VERSION ""

NS_ :

BS_:

BU_:
VAL_TABLE_ Brake_Lights 1 "True" 0 "False" ;
VAL_TABLE_ Main_Light_Switch 0 "Auto" 1 "Off" 2 "Parking light" 3 "Headlights" ;
VAL_TABLE_ Low_Beam 0 "False" 1 "True" ;
VAL_TABLE_ High_Beam 0 "False" 1 "True" ;
VAL_TABLE_ Electric_Park_Brake_Switch 0 "Not On " 1 "Release" 2 "apply" 3 "Active" ;
VAL_TABLE_ Brake_to_release_Parking_Brake 1 "True" ;
VAL_TABLE_ Parking_Brake_State 1 "Parking Brake Active" 0 "Parking Brake Inactive" ;
VAL_TABLE_ HndsOffStrWhlDtSt 0 "Hands Off" 1 "Hands On" ;
VAL_TABLE_ HndsOffStrWhlDtMd 0 "Disabled" 1 "Enabled" 2 "Failed" ;
VAL_TABLE_ ABSPr 1 "true" 0 "false" ;
VAL_TABLE_ ABSIO 1 "true" 0 "false" ;
VAL_TABLE_ AutoBrkngAvlbl 1 "true" 0 "false" ;
VAL_TABLE_ ABSActvProt 1 "true" 0 "false" ;
VAL_TABLE_ AutoBrkngAct 1 "true" 0 "false" ;
VAL_TABLE_ TCSysDisSwAtv_12A 1 "true" 0 "false" ;
VAL_TABLE_ Ky_IdDevPr 1 "true" 0 "false" ;
VAL_TABLE_ PsSbltAtc 1 "true" 0 "false" ;
VAL_TABLE_ LnCat 3 "Four Or More Lanes" 2 "Two Or Three Lanes" 1 "One lane" 0 "no info available" ;
VAL_TABLE_ RRDoorAjarSwAct 1 "true" 0 "false" ;
VAL_TABLE_ PDAjrSwAtv 1 "true" 0 "false" ;
VAL_TABLE_ DDAjrSwAtv 1 "true" 0 "false" ;
VAL_TABLE_ RLDoorAjarSwAct 1 "true" 0 "false" ;
VAL_TABLE_ DrSbltAtc 1 "true" 0 "false" ;
VAL_TABLE_ FwdClnAlrtPr 1 "true" 0 "false" ;
VAL_TABLE_ ACCAct370 1 "true" 0 "false" ;
VAL_TABLE_ DrvThrtlOvrdIO 1 "true" 0 "false" ;

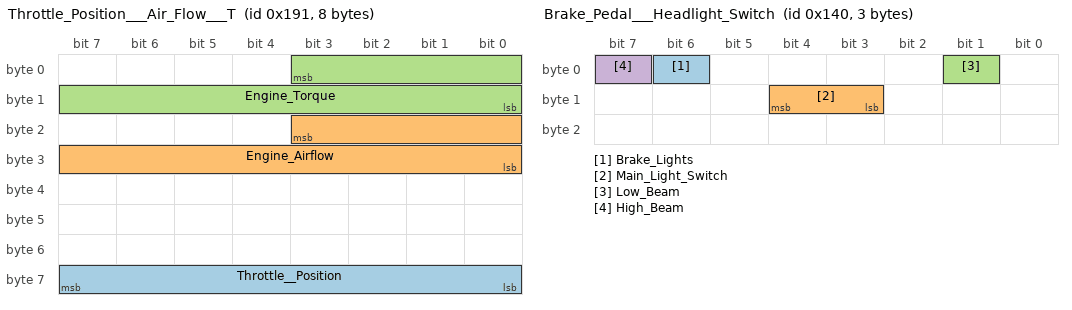
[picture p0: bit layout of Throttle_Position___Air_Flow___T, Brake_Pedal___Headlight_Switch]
BO_ 401 Throttle_Position___Air_Flow___T: 8 Vector__XXX
 SG_ Throttle__Position : 63|8@0+ (0.392157,0) [0|100.000035] "%" Vector__XXX
 SG_ Engine_Airflow : 19|12@0+ (0.5,-848) [-848|1199.5] "Nm" Vector__XXX
 SG_ Engine_Torque : 3|12@0+ (0.5,-848) [-848|1199.5] "Nm" Vector__XXX

BO_ 320 Brake_Pedal___Headlight_Switch: 3 Vector__XXX
 SG_ Brake_Lights : 6|1@0+ (1,0) [0|1] "" Vector__XXX
 SG_ Main_Light_Switch : 12|2@0+ (1,0) [0|3] "N/A" Vector__XXX
 SG_ Low_Beam : 1|1@0+ (1,0) [0|1] "" Vector__XXX
 SG_ High_Beam : 7|1@0+ (1,0) [0|1] "" Vector__XXX

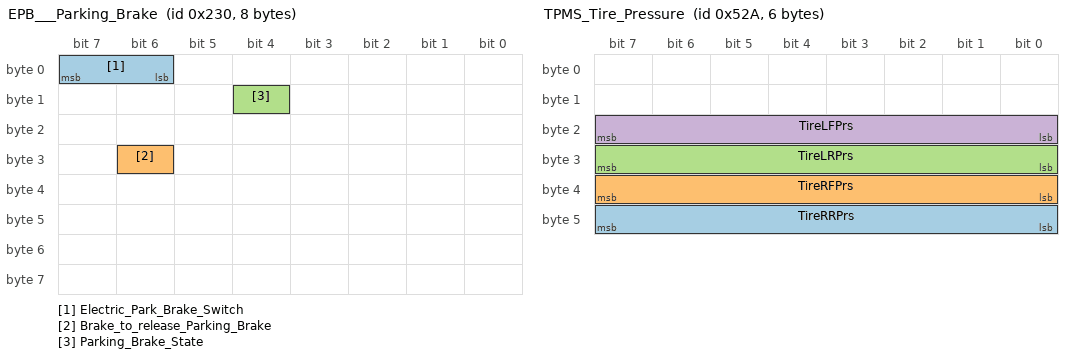
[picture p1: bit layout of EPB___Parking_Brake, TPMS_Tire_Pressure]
BO_ 560 EPB___Parking_Brake: 8 Vector__XXX
 SG_ Electric_Park_Brake_Switch : 7|2@0+ (1,0) [0|3] "" Vector__XXX
 SG_ Brake_to_release_Parking_Brake : 30|1@0+ (1,0) [0|1] "" Vector__XXX
 SG_ Parking_Brake_State : 12|1@0+ (1,0) [0|1] "" Vector__XXX

BO_ 288 ODO_Odometer: 5 Vector__XXX
 SG_ Vehicle_Odometer : 7|32@0+ (0.015625,0) [0|67108863.984375] "km" Vector__XXX

BO_ 1322 TPMS_Tire_Pressure: 6 Vector__XXX
 SG_ TireRRPrs : 47|8@0+ (4,0) [0|1020] "kPaG" CGM_HS,LVMPC_HS,EDI_HS,ICCM_OBD_HS,ICCM_HS,RDCM_HS,EBCM_OBD_HS,EBCM_HS
 SG_ TireRFPrs : 39|8@0+ (4,0) [0|1020] "kPaG" CGM_HS,LVMPC_HS,EDI_HS,ICCM_OBD_HS,ICCM_HS,RDCM_HS,EBCM_OBD_HS,EBCM_HS
 SG_ TireLRPrs : 31|8@0+ (4,0) [0|1020] "kPaG" CGM_HS,LVMPC_HS,EDI_HS,ICCM_OBD_HS,ICCM_HS,RDCM_HS,EBCM_OBD_HS,EBCM_HS
 SG_ TireLFPrs : 23|8@0+ (4,0) [0|1020] "kPaG" CGM_HS,LVMPC_HS,EDI_HS,ICCM_OBD_HS,ICCM_HS,RDCM_HS,EBCM_OBD_HS,EBCM_HS

BO_ 1020 OAT_Outside_Air_Temperature: 8 Vector__XXX
 SG_ OtsAirTmp : 31|8@0+ (0.5,-40) [-40|87.5] "deg C" CGM_HS,EPB_HS,BSM_HS,VICM_HS,PFAF_HS,BCM_HS

BO_ 388 LKA_Lane_Keeping_Assist___Active: 8 Vector__XXX
 SG_ HndsOffStrWhlDtSt : 21|1@0+ (1,0) [0|1] "" CGM_HS,EOCM_F_HS,FCM_HS
 SG_ HndsOffStrWhlDtMd : 20|2@0+ (1,0) [0|2] "" CGM_HS,EOCM_F_HS,FCM_HS

BO_ 381 ABS: 8 Vector__XXX
 SG_ ABSPr : 22|1@0+ (1,0) [0|1] "" CGM_HS,BCP_HS,APPS_HS,BCM_HS,EPB_HS
 SG_ ABSIO : 12|1@0+ (1,0) [0|1] "" CGM_HS,FCM_HS,EOCM_F_HS,BCM_HS

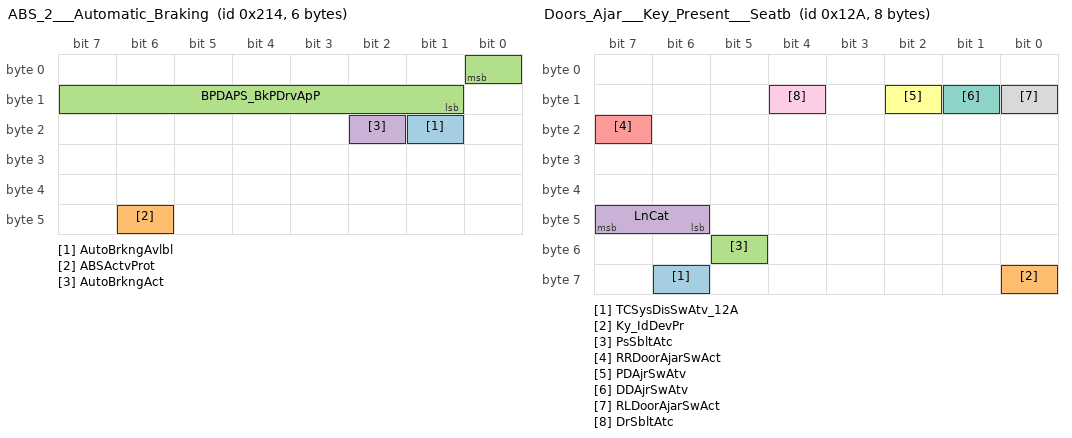
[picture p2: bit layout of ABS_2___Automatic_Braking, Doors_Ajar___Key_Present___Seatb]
BO_ 532 ABS_2___Automatic_Braking: 6 Vector__XXX
 SG_ AutoBrkngAvlbl : 17|1@0+ (1,0) [0|1] "" FCM_HS,CGM_HS,EPS_HS,EOCM_F_HS,EPB_HS
 SG_ ABSActvProt : 46|1@0+ (1,0) [0|1] "" CGM_HS,EPS_HS,EOCM_F_HS,ICCM_OBD_HS,ICCM_HS
 SG_ BPDAPS_BkPDrvApP : 0|8@0+ (75,0) [0|19125] "kPa" CGM_HS,FCM_HS,EOCM_F_HS,ICCM_OBD_HS,ICCM_HS,BCM_HS,ACC_HS,SADS_HS,EPB_HS
 SG_ AutoBrkngAct : 18|1@0+ (1,0) [0|1] "" CGM_HS,ICCM_OBD_HS,ICCM_HS,EPB_HS,ACC_HS

BO_ 298 Doors_Ajar___Key_Present___Seatb: 8 Vector__XXX
 SG_ TCSysDisSwAtv_12A : 62|1@0+ (1,0) [0|1] "" CGM_HS,ECM_HS
 SG_ Ky_IdDevPr : 56|1@0+ (1,0) [0|1] "" CGM_HS,EBCM_OBD_HS,EBCM_HS,EPB_HS
 SG_ PsSbltAtc : 53|1@0+ (1,0) [0|1] "" CGM_HS,EBCM_OBD_HS,EBCM_HS
 SG_ LnCat : 47|2@0+ (1,0) [0|3] "" CGM_HS,FCM_HS,AHL_AFL_HS
 SG_ RRDoorAjarSwAct : 23|1@0+ (1,0) [0|1] "" CGM_HS,ICCM_OBD_HS,ICCM_HS,ALC_HS,EPB_HS,SADS_HS
 SG_ PDAjrSwAtv : 10|1@0+ (1,0) [0|1] "" CGM_HS,EPB_HS,ICCM_OBD_HS,ICCM_HS,ALC_HS,SADS_HS
 SG_ DDAjrSwAtv : 9|1@0+ (1,0) [0|1] "" CGM_HS,ECM_HS,EBCM_OBD_HS,EBCM_HS,ACC_HS,EPB_HS,ICCM_OBD_HS,ICCM_HS,ALC_HS,SADS_HS
 SG_ RLDoorAjarSwAct : 8|1@0+ (1,0) [0|1] "" CGM_HS,ICCM_OBD_HS,ICCM_HS,ALC_HS,EPB_HS,SADS_HS
 SG_ DrSbltAtc : 12|1@0+ (1,0) [0|1] "" CGM_HS,ECM_HS,ACC_HS,EPB_HS,EBCM_OBD_HS,EBCM_HS

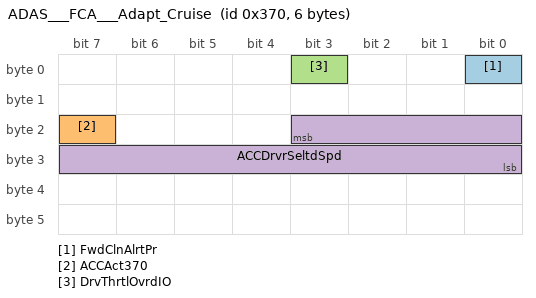
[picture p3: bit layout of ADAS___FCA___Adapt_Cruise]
BO_ 880 ADAS___FCA___Adapt_Cruise: 6 Vector__XXX
 SG_ FwdClnAlrtPr : 0|1@0+ (1,0) [0|1] "" BCM_HS
 SG_ ACCAct370 : 23|1@0+ (1,0) [0|1] "" EBCM_OBD_HS,EBCM_HS,TCM_HS,BCM_HS
 SG_ DrvThrtlOvrdIO : 3|1@0+ (1,0) [0|1] "" BCM_HS
 SG_ ACCDrvrSeltdSpd : 19|12@0+ (0.0625,0) [0|255.9375] "km / h" ECM_HS,BCM_HS

BO_ 1217 Engine_Cooling_Temperature: 8 Vector__XXX
 SG_ Engine_Cooling_Temperature_ECT : 23|8@0+ (1,-40) [-40|215] "deg C" Vector__XXX

BO_ 810 GPS_Lat_Lon: 8 Vector__XXX
 SG_ PsngSysLong : 38|31@0- (1,0) [-1073741824|1073741823] "ms arc" CGM_HS,LVMPC_HS,EBCM_OBD_HS,EBCM_HS,ACC_HS
 SG_ PsngSysLat : 5|30@0- (1,0) [-536870912|536870911] "ms arc" CGM_HS,LVMPC_HS,EBCM_OBD_HS,EBCM_HS,ACC_HS

BO_ 390 canFdStandard: 24 Vector__XXX
 SG_ signal3 : 128|8@1- (1,0) [0|255] "" Vector__XXX
 SG_ signal2 : 64|8@1- (1,0) [0|255] "" Vector__XXX
 SG_ signal1 : 0|8@1- (1,0) [0|255] "" Vector__XXX

BO_ 2633937150 TTI2: 20 Vector__XXX
 SG_ TripAirCompressorOnTime : 128|32@1+ (0.05,0) [0|210554060.75] "hr" Vector__XXX
 SG_ TripIdleTime : 96|32@1+ (0.05,0) [0|210554060.75] "hr" Vector__XXX
 SG_ TripEngRunningTime : 64|32@1+ (0.05,0) [0|210554060.75] "hr" Vector__XXX
 SG_ TripCruiseTime : 0|32@1+ (0.05,0) [0|210554060.75] "hr" Vector__XXX
 SG_ TripPTOGovernorTime : 32|32@1+ (0.05,0) [0|210554060.75] "hr" Vector__XXX

BO_ 2633938174 TTI1: 64 Vector__XXX
 SG_ TripTimeInDerateByEngHigherBits4 : 496|16@1+ (1,0) [0|4294967295] "hr" Vector__XXX
 SG_ TripTimeInDerateByEngHigherBits3 : 480|16@1+ (1,0) [0|4294967295] "hr" Vector__XXX
 SG_ TripTimeInDerateByEngHigherBits2 : 448|32@1+ (1,0) [0|4294967295] "hr" Vector__XXX
 SG_ TripTimeInDerateByEngHigherBits1 : 416|32@1+ (1,0) [0|4294967295] "hr" Vector__XXX
 SG_ TripTimeInDerateByEngMediumBits5 : 300|32@1+ (1,0) [0|4294967295] "hr" Vector__XXX
 SG_ TripTimeInDerateByEngMediumBits4 : 256|44@1+ (1,0) [0|4294967295] "hr" Vector__XXX
 SG_ TripTimeInDerateByEngMediumBits3 : 224|32@1+ (1,0) [0|4294967295] "hr" Vector__XXX
 SG_ TripTimeInDerateByEngMediumBits2 : 192|32@1+ (1,0) [0|4294967295] "hr" Vector__XXX
 SG_ TripTimeInDerateByEngMediumBits1 : 128|64@1+ (1,0) [0|4294967295] "hr" Vector__XXX
 SG_ TripTimeInDerateByEng : 96|32@1+ (0.05,0) [0|210554060.75] "hr" Vector__XXX
 SG_ TripTimeInGearDown : 64|32@1+ (0.05,0) [0|210554060.75] "hr" Vector__XXX
 SG_ TripTimeInTopGear : 32|32@1+ (0.05,0) [0|210554060.75] "hr" Vector__XXX
 SG_ TripTimeInVSL : 0|32@1+ (0.05,0) [0|210554060.75] "hr" Vector__XXX

BO_ 2566748670 AT1TI: 32 Vector__XXX
 SG_ Aftrtrtmnt1TrpNmbrOfActvRgnrtnMn : 224|32@1+ (1,0) [0|4294967295] "counts" Vector__XXX
 SG_ Aftrtrtmnt1TrpNmbrOfActvRgnrtnIn : 192|32@1+ (1,0) [0|4294967295] "counts" Vector__XXX
 SG_ Aftrtrtmnt1TrpNmbrOfPssvRgnrtns : 160|32@1+ (1,0) [0|4294967295] "counts" Vector__XXX
 SG_ Aftrtrtmnt1TrpPssvRgnrationTime : 128|32@1+ (1,0) [0|4211081215] "s" Vector__XXX
 SG_ Aftrtrtmnt1TrpNmbrOfActvRgnrtns : 96|32@1+ (1,0) [0|4294967295] "counts" Vector__XXX
 SG_ Aftertreatment1TripDisabledTime : 64|32@1+ (1,0) [0|4211081215] "s" Vector__XXX
 SG_ Aftrtrtmnt1TrpActvRgnrationTime : 32|32@1+ (1,0) [0|4211081215] "s" Vector__XXX
 SG_ Aftertreatment1TripFuelUsed : 0|32@1+ (0.5,0) [0|2105540607.5] "L" Vector__XXX

BO_ 350 AT2HI: 36 Vector__XXX
 SG_ Aftrtrtmnt2AvrgTmBtwnActvRgnrtns : 256|32@1+ (1,0) [0|4211081215] "s" Vector__XXX
 SG_ Aftrtrtmnt2TtlNmbrOfActvRgnrtnMn : 224|32@1+ (1,0) [0|4294967295] "counts" Vector__XXX
 SG_ Aftrtrtmnt2TtlNmbrOfActvRgnrtnIn : 192|32@1+ (1,0) [0|4294967295] "counts" Vector__XXX
 SG_ Aftrtrtmnt2TtlNmbrOfPssvRgnrtns : 160|32@1+ (1,0) [0|4294967295] "counts" Vector__XXX
 SG_ Aftrtrtmnt2TtlPssvRgnrationTime : 128|32@1+ (1,0) [0|4211081215] "s" Vector__XXX
 SG_ Aftrtrtmnt2TtlNmbrOfActvRgnrtns : 96|32@1+ (1,0) [0|4294967295] "counts" Vector__XXX
 SG_ Aftrtreatment2TotalDisabledTime : 64|32@1+ (1,0) [0|4211081215] "s" Vector__XXX
 SG_ Aftrtrtmnt2TtalRegenerationTime : 32|32@1+ (1,0) [0|4211081215] "s" Vector__XXX
 SG_ Aftertreatment2TotalFuelUsed : 0|32@1+ (0.5,0) [0|2105540607.5] "L" Vector__XXX

BA_DEF_ "BusType" STRING;

BA_DEF_ SG_  "SignalType" STRING ;
BA_DEF_ SG_  "SignalLongName" STRING ;
BA_DEF_ BO_  "GenMsgCycleTime" INT 0 10000;
BA_DEF_DEF_  "SignalType" "";
BA_DEF_DEF_  "SignalLongName" "";
BA_DEF_DEF_  "GenMsgCycleTime" 0;
BA_ "BusType" "CAN FD";
BA_ "GenMsgCycleTime" BO_ 401 12;
BA_ "GenMsgCycleTime" BO_ 320 1000;
BA_ "GenMsgCycleTime" BO_ 560 50;
BA_ "GenMsgCycleTime" BO_ 288 5000;
BA_ "GenMsgCycleTime" BO_ 1322 1000;
BA_ "GenMsgCycleTime" BO_ 1020 250;
BA_ "GenMsgCycleTime" BO_ 388 100;
BA_ "GenMsgCycleTime" BO_ 381 100;
BA_ "GenMsgCycleTime" BO_ 532 50;
BA_ "GenMsgCycleTime" BO_ 298 100;
BA_ "GenMsgCycleTime" BO_ 810 100;
BA_ "GenMsgCycleTime" BO_ 880 40;
BA_ "GenMsgCycleTime" BO_ 1217 500;
BA_ "GenMsgCycleTime" BO_ 390 142;
BA_ "GenMsgCycleTime" BO_ 2633937150 30;
BA_ "GenMsgCycleTime" BO_ 2633938174 30;
BA_ "GenMsgCycleTime" BO_ 350 30;
BA_ "GenMsgCycleTime" BO_ 2566748670 30;
BA_ "SignalType" SG_ 2633938174 TripTimeInDerateByEng "ENM";
BA_ "SignalType" SG_ 2633938174 TripTimeInDerateByEngHigherBits1 "ENM";
BA_ "SignalType" SG_ 2633938174 TripTimeInDerateByEngHigherBits2 "ENM";
BA_ "SignalType" SG_ 2633938174 TripTimeInDerateByEngHigherBits3 "ENM";
BA_ "SignalType" SG_ 2633938174 TripTimeInDerateByEngHigherBits4 "ENM";
BA_ "SignalType" SG_ 2633938174 TripTimeInDerateByEngMediumBits1 "ENM";
BA_ "SignalType" SG_ 2633938174 TripTimeInDerateByEngMediumBits2 "ENM";
BA_ "SignalType" SG_ 2633938174 TripTimeInDerateByEngMediumBits3 "ENM";
BA_ "SignalType" SG_ 2633938174 TripTimeInDerateByEngMediumBits4 "ENM";
BA_ "SignalType" SG_ 2633938174 TripTimeInDerateByEngMediumBits5 "ENM";
BA_ "SignalType" SG_ 2633938174 TripTimeInGearDown "ENM";
BA_ "SignalType" SG_ 2633938174 TripTimeInTopGear "ENM";
BA_ "SignalType" SG_ 2633938174 TripTimeInVSL "ENM";
BA_ "SignalType" SG_ 320 Brake_Lights "ENM";
BA_ "SignalType" SG_ 320 Main_Light_Switch "ENM";
BA_ "SignalType" SG_ 320 Low_Beam "ENM";
BA_ "SignalType" SG_ 320 High_Beam "ENM";
BA_ "SignalType" SG_ 560 Electric_Park_Brake_Switch "ENM";
BA_ "SignalType" SG_ 560 Brake_to_release_Parking_Brake "ENM";
BA_ "SignalType" SG_ 560 Parking_Brake_State "ENM";
BA_ "SignalType" SG_ 390 signal1 "ENM";
BA_ "SignalType" SG_ 390 signal2 "ENM";
BA_ "SignalType" SG_ 390 signal3 "ENM";
BA_ "SignalType" SG_ 2633937150 TripAirCompressorOnTime "ENM";
BA_ "SignalType" SG_ 2633937150 TripIdleTime "ENM";
BA_ "SignalType" SG_ 2633937150 TripEngRunningTime "ENM";
BA_ "SignalType" SG_ 2633937150 TripCruiseTime "ENM";
BA_ "SignalType" SG_ 2633937150 TripPTOGovernorTime "ENM";
BA_ "SignalType" SG_ 350 Aftrtrtmnt2TtlNmbrOfActvRgnrtnMn 1;
BA_ "SignalLongName" SG_ 350 Aftrtrtmnt2TtlNmbrOfActvRgnrtnMn "Aftrtrtmnt2TtlNmbrOfActvRgnrtnMnlRqs";
BA_ "SignalType" SG_ 350 Aftrtrtmnt2TtlNmbrOfActvRgnrtnIn 1;
BA_ "SignalLongName" SG_ 350 Aftrtrtmnt2TtlNmbrOfActvRgnrtnIn "Aftrtrtmnt2TtlNmbrOfActvRgnrtnInhbtRqs";
BA_ "SignalType" SG_ 350 Aftrtrtmnt2AvrgTmBtwnActvRgnrtns 1;
BA_ "SignalType" SG_ 350 Aftrtrtmnt2TtlNmbrOfPssvRgnrtns 1;
BA_ "SignalType" SG_ 350 Aftrtrtmnt2TtlPssvRgnrationTime 1;
BA_ "SignalType" SG_ 350 Aftrtrtmnt2TtlNmbrOfActvRgnrtns 1;
BA_ "SignalType" SG_ 350 Aftrtreatment2TotalDisabledTime 1;
BA_ "SignalType" SG_ 350 Aftrtrtmnt2TtalRegenerationTime 1;
BA_ "SignalType" SG_ 350 Aftertreatment2TotalFuelUsed 1;
BA_ "SignalType" SG_ 2566748670 Aftrtrtmnt1TrpNmbrOfActvRgnrtnMn 1;
BA_ "SignalType" SG_ 2566748670 Aftrtrtmnt1TrpNmbrOfActvRgnrtnIn 1;
BA_ "SignalType" SG_ 2566748670 Aftrtrtmnt1TrpNmbrOfPssvRgnrtns 1;
BA_ "SignalType" SG_ 2566748670 Aftrtrtmnt1TrpPssvRgnrationTime 1;
BA_ "SignalType" SG_ 2566748670 Aftrtrtmnt1TrpNmbrOfActvRgnrtns 1;
BA_ "SignalType" SG_ 2566748670 Aftertreatment1TripDisabledTime 1;
BA_ "SignalType" SG_ 2566748670 Aftrtrtmnt1TrpActvRgnrationTime 1;
BA_ "SignalType" SG_ 2566748670 Aftertreatment1TripFuelUsed 1;
BA_ "SignalLongName" SG_ 1322 TireRRPrs "Tire Right Rear Pressure";
BA_ "SignalLongName" SG_ 1322 TireRFPrs "Tire Right Front Pressure";
BA_ "SignalLongName" SG_ 1322 TireLRPrs "Tire Left Rear Pressure";
BA_ "SignalLongName" SG_ 1322 TireLFPrs "Tire Left Front Pressure";
BA_ "SignalLongName" SG_ 1020 OtsAirTmp "Outside Air Temperature";
BA_ "SignalType" SG_ 388 HndsOffStrWhlDtSt "ENM";
BA_ "SignalLongName" SG_ 388 HndsOffStrWhlDtSt "Hands Off Steering State";
BA_ "SignalType" SG_ 388 HndsOffStrWhlDtMd "ENM";
BA_ "SignalLongName" SG_ 388 HndsOffStrWhlDtMd "Hands Off Steering Mode";
BA_ "SignalType" SG_ 381 ABSPr "ENM";
BA_ "SignalLongName" SG_ 381 ABSPr "ABS  Present";
BA_ "SignalType" SG_ 381 ABSIO "ENM";
BA_ "SignalLongName" SG_ 381 ABSIO "ABS Indication On";
BA_ "SignalType" SG_ 532 AutoBrkngAvlbl "ENM";
BA_ "SignalLongName" SG_ 532 AutoBrkngAvlbl "Auto Braking available";
BA_ "SignalType" SG_ 532 ABSActvProt "ENM";
BA_ "SignalLongName" SG_ 532 ABSActvProt "Antilock Brake  Active";
BA_ "SignalLongName" SG_ 532 BPDAPS_BkPDrvApP "Brake Pedal Pressure";
BA_ "SignalType" SG_ 532 AutoBrkngAct "ENM";
BA_ "SignalLongName" SG_ 532 AutoBrkngAct "Auto Braking Active";
BA_ "SignalType" SG_ 298 TCSysDisSwAtv_12A "ENM";
BA_ "SignalLongName" SG_ 298 TCSysDisSwAtv_12A "Traction Control System Disable Switch";
BA_ "SignalType" SG_ 298 Ky_IdDevPr "ENM";
BA_ "SignalLongName" SG_ 298 Ky_IdDevPr "Key  Present";
BA_ "SignalType" SG_ 298 PsSbltAtc "ENM";
BA_ "SignalLongName" SG_ 298 PsSbltAtc "Passenger Seatbelt Attached";
BA_ "SignalType" SG_ 298 LnCat "ENM";
BA_ "SignalLongName" SG_ 298 LnCat "Lane Category";
BA_ "SignalType" SG_ 298 RRDoorAjarSwAct "ENM";
BA_ "SignalLongName" SG_ 298 RRDoorAjarSwAct "Rear Right Door Ajar Switch";
BA_ "SignalType" SG_ 298 PDAjrSwAtv "ENM";
BA_ "SignalLongName" SG_ 298 PDAjrSwAtv "Passenger Door Ajar Switch";
BA_ "SignalType" SG_ 298 DDAjrSwAtv "ENM";
BA_ "SignalLongName" SG_ 298 DDAjrSwAtv "Driver Door Ajar Switch";
BA_ "SignalType" SG_ 298 RLDoorAjarSwAct "ENM";
BA_ "SignalLongName" SG_ 298 RLDoorAjarSwAct "Rear Left Door Ajar Switch";
BA_ "SignalType" SG_ 298 DrSbltAtc "ENM";
BA_ "SignalLongName" SG_ 298 DrSbltAtc "Driver Seatbelt Attached";
BA_ "SignalType" SG_ 880 FwdClnAlrtPr "ENM";
BA_ "SignalLongName" SG_ 880 FwdClnAlrtPr "Forward Collision Alert";
BA_ "SignalType" SG_ 880 ACCAct370 "ENM";
BA_ "SignalLongName" SG_ 880 ACCAct370 "Adaptive Cruise Active";
BA_ "SignalType" SG_ 880 DrvThrtlOvrdIO "ENM";
BA_ "SignalLongName" SG_ 880 DrvThrtlOvrdIO "Throttle Override Indication";
BA_ "SignalLongName" SG_ 880 ACCDrvrSeltdSpd "Adaptive Cruise Selected Speed";
BA_ "SignalLongName" SG_ 810 PsngSysLong "Positioning   Longitude";
BA_ "SignalLongName" SG_ 810 PsngSysLat "Positioning   Latitude";
VAL_ 320 Brake_Lights 1 "True" 0 "False" ;
VAL_ 320 Main_Light_Switch 0 "Auto" 1 "Off" 2 "Parking light" 3 "Headlights" ;
VAL_ 320 Low_Beam 0 "False" 1 "True" ;
VAL_ 320 High_Beam 0 "False" 1 "True" ;
VAL_ 560 Electric_Park_Brake_Switch 0 "Not On " 1 "Release" 2 "apply" 3 "Active" ;
VAL_ 560 Brake_to_release_Parking_Brake 1 "True" ;
VAL_ 560 Parking_Brake_State 1 "Parking Brake Active" 0 "Parking Brake Inactive" ;
VAL_ 388 HndsOffStrWhlDtSt 0 "Hands Off" 1 "Hands On" ;
VAL_ 388 HndsOffStrWhlDtMd 0 "Disabled" 1 "Enabled" 2 "Failed" ;
VAL_ 381 ABSPr 1 "true" 0 "false" ;
VAL_ 381 ABSIO 1 "true" 0 "false" ;
VAL_ 532 AutoBrkngAvlbl 1 "true" 0 "false" ;
VAL_ 532 ABSActvProt 1 "true" 0 "false" ;
VAL_ 532 AutoBrkngAct 1 "true" 0 "false" ;
VAL_ 298 TCSysDisSwAtv_12A 1 "true" 0 "false" ;
VAL_ 298 Ky_IdDevPr 1 "true" 0 "false" ;
VAL_ 298 PsSbltAtc 1 "true" 0 "false" ;
VAL_ 298 LnCat 3 "Four Or More Lanes" 2 "Two Or Three Lanes" 1 "One lane" 0 "no info available" ;
VAL_ 298 RRDoorAjarSwAct 1 "true" 0 "false" ;
VAL_ 298 PDAjrSwAtv 1 "true" 0 "false" ;
VAL_ 298 DDAjrSwAtv 1 "true" 0 "false" ;
VAL_ 298 RLDoorAjarSwAct 1 "true" 0 "false" ;
VAL_ 298 DrSbltAtc 1 "true" 0 "false" ;
VAL_ 880 FwdClnAlrtPr 1 "true" 0 "false" ;
VAL_ 880 ACCAct370 1 "true" 0 "false" ;
VAL_ 880 DrvThrtlOvrdIO 1 "true" 0 "false" ;
